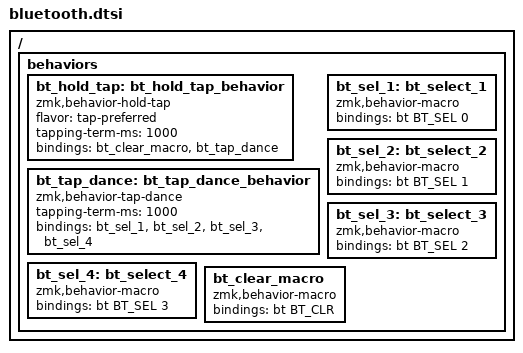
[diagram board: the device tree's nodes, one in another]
/ {
    behaviors {
        bt_hold_tap: bt_hold_tap_behavior {
            compatible = "zmk,behavior-hold-tap";
            #binding-cells = <2>;
            flavor = "tap-preferred";
            tapping-term-ms = <1000>;
            bindings = <&bt_clear_macro>, <&bt_tap_dance>;
        };

        bt_tap_dance: bt_tap_dance_behavior {
            compatible = "zmk,behavior-tap-dance";
            #binding-cells = <0>;
            tapping-term-ms = <1000>;
            bindings = <&bt_sel_1>, <&bt_sel_2>, <&bt_sel_3>, <&bt_sel_4>;
        };

        bt_sel_1: bt_select_1 {
            compatible = "zmk,behavior-macro";
            #binding-cells = <0>;
            bindings = <&bt BT_SEL 0>;
        };

        bt_sel_2: bt_select_2 {
            compatible = "zmk,behavior-macro";
            #binding-cells = <0>;
            bindings = <&bt BT_SEL 1>;
        };

        bt_sel_3: bt_select_3 {
            compatible = "zmk,behavior-macro";
            #binding-cells = <0>;
            bindings = <&bt BT_SEL 2>;
        };

        bt_sel_4: bt_select_4 {
            compatible = "zmk,behavior-macro";
            #binding-cells = <0>;
            bindings = <&bt BT_SEL 3>;
        };

        bt_clear_macro: bt_clear_macro {
            compatible = "zmk,behavior-macro";
            #binding-cells = <0>;
            bindings = <&bt BT_CLR>;
        };
    };
};
